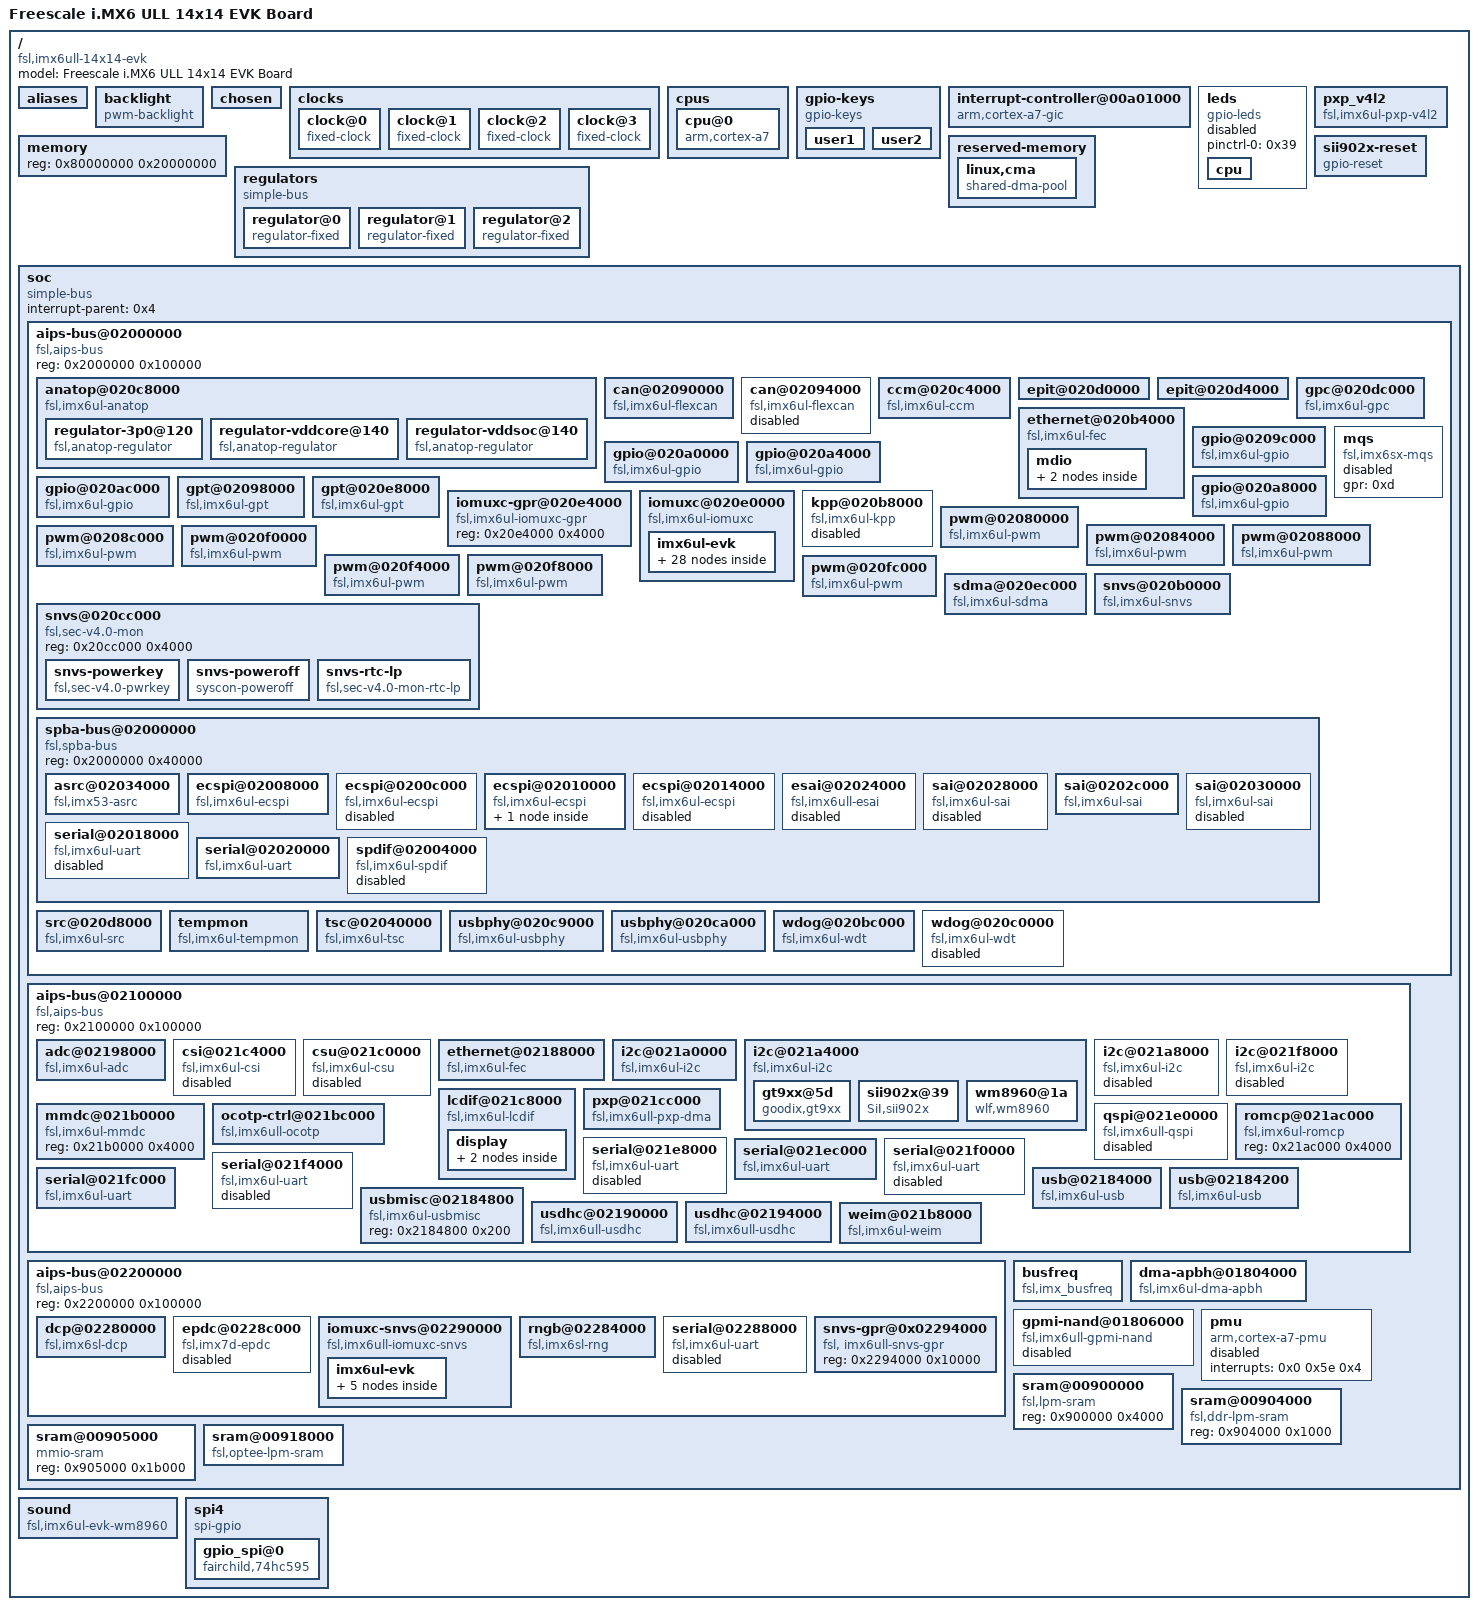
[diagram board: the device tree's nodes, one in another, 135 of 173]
/dts-v1/;

/memreserve/	0x0000000083000000 0x000000000000a000;
/ {
	#address-cells = <0x1>;
	#size-cells = <0x1>;
	compatible = "fsl,imx6ull-14x14-evk", "fsl,imx6ull";
	model = "Freescale i.MX6 ULL 14x14 EVK Board";

	aliases {
		can0 = "/soc/aips-bus@02000000/can@02090000";
		can1 = "/soc/aips-bus@02000000/can@02094000";
		ethernet0 = "/soc/aips-bus@02100000/ethernet@02188000";
		ethernet1 = "/soc/aips-bus@02000000/ethernet@020b4000";
		gpio0 = "/soc/aips-bus@02000000/gpio@0209c000";
		gpio1 = "/soc/aips-bus@02000000/gpio@020a0000";
		gpio2 = "/soc/aips-bus@02000000/gpio@020a4000";
		gpio3 = "/soc/aips-bus@02000000/gpio@020a8000";
		gpio4 = "/soc/aips-bus@02000000/gpio@020ac000";
		i2c0 = "/soc/aips-bus@02100000/i2c@021a0000";
		i2c1 = "/soc/aips-bus@02100000/i2c@021a4000";
		i2c2 = "/soc/aips-bus@02100000/i2c@021a8000";
		i2c3 = "/soc/aips-bus@02100000/i2c@021f8000";
		mmc0 = "/soc/aips-bus@02100000/usdhc@02190000";
		mmc1 = "/soc/aips-bus@02100000/usdhc@02194000";
		serial0 = "/soc/aips-bus@02000000/spba-bus@02000000/serial@02020000";
		serial1 = "/soc/aips-bus@02100000/serial@021e8000";
		serial2 = "/soc/aips-bus@02100000/serial@021ec000";
		serial3 = "/soc/aips-bus@02100000/serial@021f0000";
		serial4 = "/soc/aips-bus@02100000/serial@021f4000";
		serial5 = "/soc/aips-bus@02100000/serial@021fc000";
		serial6 = "/soc/aips-bus@02000000/spba-bus@02000000/serial@02018000";
		serial7 = "/soc/aips-bus@02200000/serial@02288000";
		spi0 = "/soc/aips-bus@02000000/spba-bus@02000000/ecspi@02008000";
		spi1 = "/soc/aips-bus@02000000/spba-bus@02000000/ecspi@0200c000";
		spi2 = "/soc/aips-bus@02000000/spba-bus@02000000/ecspi@02010000";
		spi3 = "/soc/aips-bus@02000000/spba-bus@02000000/ecspi@02014000";
		usbphy0 = "/soc/aips-bus@02000000/usbphy@020c9000";
		usbphy1 = "/soc/aips-bus@02000000/usbphy@020ca000";
	};

	backlight {
		brightness-levels = <0x0 0x1 0x2 0x3 0x4 0x5 0x6 0x8 0xa>;
		compatible = "pwm-backlight";
		default-brightness-level = <0x8>;
		pwms = <0x38 0x0 0x3e8>;
		status = "okay";
	};

	chosen {
		bootargs = "console=ttymxc0,115200 root=/dev/mmcblk1p2 rootwait rw";
		stdout-path = "/soc/aips-bus@02000000/spba-bus@02000000/serial@02020000";
	};

	clocks {
		#address-cells = <0x1>;
		#size-cells = <0x0>;

		clock@0 {
			#clock-cells = <0x0>;
			clock-frequency = <0x8000>;
			clock-output-names = "ckil";
			compatible = "fixed-clock";
			linux,phandle = <0x16>;
			phandle = <0x16>;
			reg = <0x0>;
		};

		clock@1 {
			#clock-cells = <0x0>;
			clock-frequency = <0x16e3600>;
			clock-output-names = "osc";
			compatible = "fixed-clock";
			linux,phandle = <0x17>;
			phandle = <0x17>;
			reg = <0x1>;
		};

		clock@2 {
			#clock-cells = <0x0>;
			clock-frequency = <0x0>;
			clock-output-names = "ipp_di0";
			compatible = "fixed-clock";
			linux,phandle = <0x18>;
			phandle = <0x18>;
			reg = <0x2>;
		};

		clock@3 {
			#clock-cells = <0x0>;
			clock-frequency = <0x0>;
			clock-output-names = "ipp_di1";
			compatible = "fixed-clock";
			linux,phandle = <0x19>;
			phandle = <0x19>;
			reg = <0x3>;
		};
	};

	cpus {
		#address-cells = <0x1>;
		#size-cells = <0x0>;

		cpu@0 {
			arm-supply = <0x2>;
			clock-latency = <0xee6c>;
			clock-names = "arm", "pll2_bus", "pll2_pfd2_396m", "secondary_sel", "step", "pll1_sw", "pll1_sys", "pll1_bypass", "pll1", "pll1_bypass_src", "osc";
			clocks = <0x1 0x5d 0x1 0x1a 0x1 0x26 0x1 0xdb 0x1 0x38 0x1 0x39 0x1 0x19 0x1 0x12 0x1 0xb 0x1 0x4 0x1 0x3>;
			compatible = "arm,cortex-a7";
			device_type = "cpu";
			fsl,low-power-run;
			fsl,soc-operating-points = <0xdbba0 0x11edd8 0xc15c0 0x11edd8 0x80e80 0x11edd8 0x60ae0 0x11edd8 0x30570 0x11edd8>;
			operating-points = <0xdbba0 0x137478 0xc15c0 0x12b128 0x80e80 0x11edd8 0x60ae0 0xfa3e8 0x30570 0xe7ef0>;
			reg = <0x0>;
			soc-supply = <0x3>;
		};
	};

	gpio-keys {
		compatible = "gpio-keys";
		pinctrl-names = "default";

		user1 {
			gpio-key,wakeup;
			gpios = <0x15 0x1 0x1>;
			label = "User1 Button";
			linux,code = <0x2>;
		};

		user2 {
			gpio-key,wakeup;
			gpios = <0x9 0xe 0x1>;
			label = "User2 Button";
			linux,code = <0x3>;
		};
	};

	interrupt-controller@00a01000 {
		#interrupt-cells = <0x3>;
		compatible = "arm,cortex-a7-gic";
		interrupt-controller;
		linux,phandle = <0x1e>;
		phandle = <0x1e>;
		reg = <0xa01000 0x1000 0xa02000 0x100>;
	};

	leds {
		compatible = "gpio-leds";
		pinctrl-0 = <0x39>;
		pinctrl-names = "default";
		status = "disabled";

		cpu {
			default-state = "on";
			gpios = <0x15 0x3 0x1>;
			label = "cpu";
			linux,default-trigger = "heartbeat";
		};
	};

	memory {
		device_type = "memory";
		reg = <0x80000000 0x20000000>;
	};

	pxp_v4l2 {
		compatible = "fsl,imx6ul-pxp-v4l2", "fsl,imx6sx-pxp-v4l2", "fsl,imx6sl-pxp-v4l2";
		status = "okay";
	};

	regulators {
		#address-cells = <0x1>;
		#size-cells = <0x0>;
		compatible = "simple-bus";

		regulator@0 {
			compatible = "regulator-fixed";
			linux,phandle = <0x12>;
			phandle = <0x12>;
			reg = <0x0>;
			regulator-max-microvolt = <0x325aa0>;
			regulator-min-microvolt = <0x325aa0>;
			regulator-name = "can-3v3";
		};

		regulator@1 {
			compatible = "regulator-fixed";
			enable-active-high;
			gpios = <0x15 0x5 0x0>;
			regulator-boot-on;
			regulator-max-microvolt = <0x39fbc0>;
			regulator-min-microvolt = <0x39fbc0>;
			regulator-name = "ltemodule-pwr";
		};

		regulator@2 {
			compatible = "regulator-fixed";
			gpios = <0xb 0xa 0x1>;
			regulator-boot-on;
			regulator-max-microvolt = <0x325aa0>;
			regulator-min-microvolt = <0x325aa0>;
			regulator-name = "wifi-pwr";
		};
	};

	reserved-memory {
		#address-cells = <0x1>;
		#size-cells = <0x1>;
		ranges;

		linux,cma {
			compatible = "shared-dma-pool";
			linux,cma-default;
			reusable;
			size = <0x14000000>;
		};
	};

	sii902x-reset {
		#reset-cells = <0x0>;
		compatible = "gpio-reset";
		linux,phandle = <0x2b>;
		phandle = <0x2b>;
		reset-delay-us = <0x186a0>;
		reset-gpios = <0x3e 0x1 0x1>;
		status = "okay";
	};

	soc {
		#address-cells = <0x1>;
		#size-cells = <0x1>;
		compatible = "simple-bus";
		interrupt-parent = <0x4>;
		ranges;

		aips-bus@02000000 {
			#address-cells = <0x1>;
			#size-cells = <0x1>;
			compatible = "fsl,aips-bus", "simple-bus";
			ranges;
			reg = <0x2000000 0x100000>;

			anatop@020c8000 {
				compatible = "fsl,imx6ul-anatop", "fsl,imx6q-anatop", "syscon", "simple-bus";
				interrupts = <0x0 0x31 0x4 0x0 0x36 0x4 0x0 0x7f 0x4>;
				linux,phandle = <0x1b>;
				phandle = <0x1b>;
				reg = <0x20c8000 0x1000>;

				regulator-3p0@120 {
					anatop-enable-bit = <0x0>;
					anatop-max-voltage = <0x33e140>;
					anatop-min-bit-val = <0x0>;
					anatop-min-voltage = <0x280de8>;
					anatop-reg-offset = <0x120>;
					anatop-vol-bit-shift = <0x8>;
					anatop-vol-bit-width = <0x5>;
					compatible = "fsl,anatop-regulator";
					linux,phandle = <0x1a>;
					phandle = <0x1a>;
					regulator-max-microvolt = <0x33e140>;
					regulator-min-microvolt = <0x280de8>;
					regulator-name = "vdd3p0";
				};

				regulator-vddcore@140 {
					anatop-delay-bit-shift = <0x18>;
					anatop-delay-bit-width = <0x2>;
					anatop-delay-reg-offset = <0x170>;
					anatop-max-voltage = <0x162010>;
					anatop-min-bit-val = <0x1>;
					anatop-min-voltage = <0xb1008>;
					anatop-reg-offset = <0x140>;
					anatop-vol-bit-shift = <0x0>;
					anatop-vol-bit-width = <0x5>;
					compatible = "fsl,anatop-regulator";
					linux,phandle = <0x2>;
					phandle = <0x2>;
					regulator-always-on;
					regulator-max-microvolt = <0x162010>;
					regulator-min-microvolt = <0xb1008>;
					regulator-name = "cpu";
				};

				regulator-vddsoc@140 {
					anatop-delay-bit-shift = <0x1c>;
					anatop-delay-bit-width = <0x2>;
					anatop-delay-reg-offset = <0x170>;
					anatop-max-voltage = <0x162010>;
					anatop-min-bit-val = <0x1>;
					anatop-min-voltage = <0xb1008>;
					anatop-reg-offset = <0x140>;
					anatop-vol-bit-shift = <0x12>;
					anatop-vol-bit-width = <0x5>;
					compatible = "fsl,anatop-regulator";
					linux,phandle = <0x3>;
					phandle = <0x3>;
					regulator-always-on;
					regulator-max-microvolt = <0x162010>;
					regulator-min-microvolt = <0xb1008>;
					regulator-name = "vddsoc";
				};
			};

			can@02090000 {
				clock-names = "ipg", "per";
				clocks = <0x1 0x94 0x1 0x95>;
				compatible = "fsl,imx6ul-flexcan", "fsl,imx6q-flexcan";
				interrupts = <0x0 0x6e 0x4>;
				pinctrl-0 = <0x11>;
				pinctrl-names = "default";
				reg = <0x2090000 0x4000>;
				status = "okay";
				stop-mode = <0xd 0x10 0x1 0x10 0x11>;
				xceiver-supply = <0x12>;
			};

			can@02094000 {
				clock-names = "ipg", "per";
				clocks = <0x1 0x96 0x1 0x97>;
				compatible = "fsl,imx6ul-flexcan", "fsl,imx6q-flexcan";
				interrupts = <0x0 0x6f 0x4>;
				reg = <0x2094000 0x4000>;
				status = "disabled";
				stop-mode = <0xd 0x10 0x2 0x10 0x12>;
			};

			ccm@020c4000 {
				#clock-cells = <0x1>;
				assigned-clock-rates = <0x2ee00000>;
				assigned-clocks = <0x1 0x32>;
				clock-names = "ckil", "osc", "ipp_di0", "ipp_di1";
				clocks = <0x16 0x17 0x18 0x19>;
				compatible = "fsl,imx6ul-ccm";
				interrupts = <0x0 0x57 0x4 0x0 0x58 0x4>;
				linux,phandle = <0x1>;
				phandle = <0x1>;
				reg = <0x20c4000 0x4000>;
			};

			epit@020d0000 {
				interrupts = <0x0 0x38 0x4>;
				reg = <0x20d0000 0x4000>;
			};

			epit@020d4000 {
				interrupts = <0x0 0x39 0x4>;
				reg = <0x20d4000 0x4000>;
			};

			ethernet@020b4000 {
				clock-names = "ipg", "ahb", "ptp", "enet_clk_ref", "enet_out";
				clocks = <0x1 0x90 0x1 0x91 0x1 0x30 0x1 0x2e 0x1 0x2e>;
				compatible = "fsl,imx6ul-fec", "fsl,imx6q-fec";
				fsl,magic-packet;
				fsl,num-rx-queues = <0x1>;
				fsl,num-tx-queues = <0x1>;
				fsl,wakeup_irq = <0x0>;
				interrupts = <0x0 0x78 0x4 0x0 0x79 0x4>;
				local-mac-address = [00 01 3f 2d 3e 4d];
				phy-handle = <0x14>;
				phy-mode = "rmii";
				phy-reset-duration = <0x1a>;
				phy-reset-gpios = <0x15 0x6 0x1>;
				pinctrl-0 = <0x13>;
				pinctrl-names = "default";
				reg = <0x20b4000 0x4000>;
				status = "okay";
				stop-mode = <0xd 0x10 0x4>;

				mdio {
					#address-cells = <0x1>;
					#size-cells = <0x0>;

					ethernet-phy@0 {
						compatible = "ethernet-phy-ieee802.3-c22";
						linux,phandle = <0x24>;
						phandle = <0x24>;
						reg = <0x0>;
						smsc,disable-energy-detect;
					};

					ethernet-phy@1 {
						compatible = "ethernet-phy-ieee802.3-c22";
						linux,phandle = <0x14>;
						phandle = <0x14>;
						reg = <0x1>;
						smsc,disable-energy-detect;
					};
				};
			};

			gpc@020dc000 {
				#interrupt-cells = <0x3>;
				compatible = "fsl,imx6ul-gpc", "fsl,imx6q-gpc";
				fsl,cpu_pdnscr_iso = <0x1>;
				fsl,cpu_pdnscr_iso2sw = <0x1>;
				fsl,cpu_pupscr_sw = <0x0>;
				fsl,cpu_pupscr_sw2iso = <0x1>;
				fsl,ldo-bypass = <0x0>;
				fsl,mf-mix-wakeup-irq = <0xfc00000 0x7d00 0x0 0x1400640>;
				interrupt-controller;
				interrupt-parent = <0x1e>;
				interrupts = <0x0 0x59 0x4>;
				linux,phandle = <0x4>;
				phandle = <0x4>;
				reg = <0x20dc000 0x4000>;
			};

			gpio@0209c000 {
				#gpio-cells = <0x2>;
				#interrupt-cells = <0x2>;
				compatible = "fsl,imx6ul-gpio", "fsl,imx35-gpio";
				gpio-controller;
				interrupt-controller;
				interrupts = <0x0 0x42 0x4 0x0 0x43 0x4>;
				linux,phandle = <0xb>;
				phandle = <0xb>;
				reg = <0x209c000 0x4000>;
			};

			gpio@020a0000 {
				#gpio-cells = <0x2>;
				#interrupt-cells = <0x2>;
				compatible = "fsl,imx6ul-gpio", "fsl,imx35-gpio";
				gpio-controller;
				interrupt-controller;
				interrupts = <0x0 0x44 0x4 0x0 0x45 0x4>;
				reg = <0x20a0000 0x4000>;
			};

			gpio@020a4000 {
				#gpio-cells = <0x2>;
				#interrupt-cells = <0x2>;
				compatible = "fsl,imx6ul-gpio", "fsl,imx35-gpio";
				gpio-controller;
				interrupt-controller;
				interrupts = <0x0 0x46 0x4 0x0 0x47 0x4>;
				linux,phandle = <0x32>;
				phandle = <0x32>;
				reg = <0x20a4000 0x4000>;
			};

			gpio@020a8000 {
				#gpio-cells = <0x2>;
				#interrupt-cells = <0x2>;
				compatible = "fsl,imx6ul-gpio", "fsl,imx35-gpio";
				gpio-controller;
				interrupt-controller;
				interrupts = <0x0 0x48 0x4 0x0 0x49 0x4>;
				linux,phandle = <0x9>;
				phandle = <0x9>;
				reg = <0x20a8000 0x4000>;
			};

			gpio@020ac000 {
				#gpio-cells = <0x2>;
				#interrupt-cells = <0x2>;
				compatible = "fsl,imx6ul-gpio", "fsl,imx35-gpio";
				gpio-controller;
				interrupt-controller;
				interrupts = <0x0 0x4a 0x4 0x0 0x4b 0x4>;
				linux,phandle = <0x15>;
				phandle = <0x15>;
				reg = <0x20ac000 0x4000>;
			};

			gpt@02098000 {
				clock-names = "ipg", "osc_per";
				clocks = <0x1 0x98 0x1 0xd6>;
				compatible = "fsl,imx6ul-gpt", "fsl,imx31-gpt";
				interrupts = <0x0 0x37 0x4>;
				reg = <0x2098000 0x4000>;
			};

			gpt@020e8000 {
				clock-names = "ipg", "per";
				clocks = <0x1 0x0 0x1 0x0>;
				compatible = "fsl,imx6ul-gpt", "fsl,imx31-gpt";
				interrupts = <0x0 0x6d 0x4>;
				reg = <0x20e8000 0x4000>;
			};

			iomuxc-gpr@020e4000 {
				compatible = "fsl,imx6ul-iomuxc-gpr", "fsl,imx6q-iomuxc-gpr", "syscon";
				linux,phandle = <0xd>;
				phandle = <0xd>;
				reg = <0x20e4000 0x4000>;
			};

			iomuxc@020e0000 {
				compatible = "fsl,imx6ul-iomuxc";
				pinctrl-0 = <0x1f>;
				pinctrl-names = "default";
				reg = <0x20e0000 0x4000>;

				imx6ul-evk {

					adc1grp {
						fsl,pins = <0x68 0x2f4 0x0 0x5 0x0 0x10b1 0x6c 0x2f8 0x0 0x5 0x0 0x10b1>;
						linux,phandle = <0x27>;
						phandle = <0x27>;
					};

					ecspi1 {
						fsl,pins = <0x1f4 0x480 0x534 0x3 0x1 0x10b0 0x1fc 0x488 0x53c 0x3 0x1 0x10b0 0x200 0x48c 0x538 0x3 0x1 0x10b0 0x1f8 0x484 0x0 0x5 0x0 0x10b0 0x1f0 0x47c 0x0 0x5 0x0 0x10b0>;
						linux,phandle = <0x8>;
						phandle = <0x8>;
					};

					ecspi3 {
						fsl,pins = <0x9c 0x328 0x55c 0x8 0x0 0x10b0 0xa0 0x32c 0x558 0x8 0x0 0x10b0 0x98 0x324 0x554 0x8 0x0 0x10b0 0x94 0x320 0x0 0x5 0x0 0x10b0 0x60 0x2ec 0x0 0x5 0x0 0x10b0>;
						linux,phandle = <0xa>;
						phandle = <0xa>;
					};

					enet1grp {
						fsl,pins;
						linux,phandle = <0x23>;
						phandle = <0x23>;
					};

					enet2grp {
						fsl,pins = <0x74 0x300 0x580 0x1 0x0 0x1b0b0 0x78 0x304 0x0 0x1 0x0 0x1b0b0 0xec 0x378 0x0 0x0 0x0 0x1b0b0 0x100 0x38c 0x0 0x0 0x0 0x1b0b0 0xe4 0x370 0x0 0x0 0x0 0x1b0b0 0xe8 0x374 0x0 0x0 0x0 0x1b0b0 0xf8 0x384 0x0 0x0 0x0 0x1b0b0 0xf0 0x37c 0x0 0x0 0x0 0x1b0b0 0xf4 0x380 0x0 0x0 0x0 0x1b0b0 0xfc 0x388 0x57c 0x4 0x2 0x4001b031 0xcc 0x358 0x0 0x0 0x0 0x1b0b0 0xe0 0x36c 0x0 0x0 0x0 0x1b0b0 0xc4 0x350 0x0 0x0 0x0 0x1b0b0 0xc8 0x354 0x0 0x0 0x0 0x1b0b0 0xd8 0x364 0x0 0x0 0x0 0x1b0b0 0xd0 0x35c 0x0 0x0 0x0 0x1b0b0 0xd4 0x360 0x0 0x0 0x0 0x1b0b0 0xdc 0x368 0x574 0x4 0x2 0x4001b031>;
						linux,phandle = <0x13>;
						phandle = <0x13>;
					};

					flexcan1grp {
						fsl,pins = <0xac 0x338 0x0 0x2 0x0 0x10b0 0xb0 0x33c 0x584 0x2 0x0 0x10b0>;
						linux,phandle = <0x11>;
						phandle = <0x11>;
					};

					hdmigrp {
						fsl,pins = <0x8c 0x318 0x0 0x5 0x0 0x59>;
						linux,phandle = <0x2a>;
						phandle = <0x2a>;
					};

					hoggrp-1 {
						fsl,pins = <0x90 0x31c 0x0 0x5 0x0 0x17059 0x5c 0x2e8 0x4b8 0x2 0x0 0x17059 0x1c 0x60 0x0 0x5 0x0 0x110a0>;
						linux,phandle = <0x1f>;
						phandle = <0x1f>;
					};

					i2c1grp {
						fsl,pins = <0xb4 0x340 0x5a4 0x2 0x1 0x4001b8b0 0xb8 0x344 0x5a8 0x2 0x2 0x4001b8b0>;
						linux,phandle = <0x28>;
						phandle = <0x28>;
					};

					i2c2grp {
						fsl,pins = <0xbc 0x348 0x5ac 0x2 0x2 0x4001b8b0 0xc0 0x34c 0x5b0 0x2 0x2 0x4001b8b0>;
						linux,phandle = <0x29>;
						phandle = <0x29>;
					};

					lcdif_tsc_int {
						fsl,pins = <0x70 0x2fc 0x0 0x5 0x0 0x10b0>;
						linux,phandle = <0x2d>;
						phandle = <0x2d>;
					};

					lcdifctrlgrp {
						fsl,pins = <0x104 0x390 0x0 0x0 0x0 0x79 0x108 0x394 0x0 0x0 0x0 0x79 0x10c 0x398 0x5dc 0x0 0x0 0x79 0x110 0x39c 0x0 0x0 0x0 0x79>;
						linux,phandle = <0x2f>;
						phandle = <0x2f>;
					};

					lcdifdatgrp {
						fsl,pins = <0x118 0x3a4 0x0 0x0 0x0 0x79 0x11c 0x3a8 0x0 0x0 0x0 0x79 0x120 0x3ac 0x0 0x0 0x0 0x79 0x124 0x3b0 0x0 0x0 0x0 0x79 0x128 0x3b4 0x0 0x0 0x0 0x79 0x12c 0x3b8 0x0 0x0 0x0 0x79 0x130 0x3bc 0x0 0x0 0x0 0x79 0x134 0x3c0 0x0 0x0 0x0 0x79 0x138 0x3c4 0x0 0x0 0x0 0x79 0x13c 0x3c8 0x0 0x0 0x0 0x79 0x140 0x3cc 0x0 0x0 0x0 0x79 0x144 0x3d0 0x0 0x0 0x0 0x79 0x148 0x3d4 0x0 0x0 0x0 0x79 0x14c 0x3d8 0x0 0x0 0x0 0x79 0x150 0x3dc 0x0 0x0 0x0 0x79 0x154 0x3e0 0x0 0x0 0x0 0x79 0x158 0x3e4 0x0 0x0 0x0 0x79 0x15c 0x3e8 0x0 0x0 0x0 0x79 0x160 0x3ec 0x0 0x0 0x0 0x79 0x164 0x3f0 0x0 0x0 0x0 0x79 0x168 0x3f4 0x0 0x0 0x0 0x79 0x16c 0x3f8 0x0 0x0 0x0 0x79 0x170 0x3fc 0x0 0x0 0x0 0x79 0x174 0x400 0x0 0x0 0x0 0x79>;
						linux,phandle = <0x2e>;
						phandle = <0x2e>;
					};

					lcdifdatgrp_16bits {
						fsl,pins = <0x118 0x3a4 0x0 0x0 0x0 0x79 0x11c 0x3a8 0x0 0x0 0x0 0x79 0x120 0x3ac 0x0 0x0 0x0 0x79 0x124 0x3b0 0x0 0x0 0x0 0x79 0x128 0x3b4 0x0 0x0 0x0 0x79 0x12c 0x3b8 0x0 0x0 0x0 0x79 0x130 0x3bc 0x0 0x0 0x0 0x79 0x134 0x3c0 0x0 0x0 0x0 0x79 0x138 0x3c4 0x0 0x0 0x0 0x79 0x13c 0x3c8 0x0 0x0 0x0 0x79 0x140 0x3cc 0x0 0x0 0x0 0x79 0x144 0x3d0 0x0 0x0 0x0 0x79 0x148 0x3d4 0x0 0x0 0x0 0x79 0x14c 0x3d8 0x0 0x0 0x0 0x79 0x150 0x3dc 0x0 0x0 0x0 0x79 0x154 0x3e0 0x0 0x0 0x0 0x79>;
					};

					lcdifresetgrp {
						fsl,pins = <0x114 0x3a0 0x0 0x5 0x0 0x1b0b0>;
						linux,phandle = <0x30>;
						phandle = <0x30>;
					};

					pwm1grp {
						fsl,pins = <0x7c 0x308 0x0 0x0 0x0 0x110b0>;
						linux,phandle = <0x10>;
						phandle = <0x10>;
					};

					sai2grp {
						fsl,pins = <0x50 0x2dc 0x5f8 0x2 0x0 0x17088 0x4c 0x2d8 0x5fc 0x2 0x0 0x17088 0x58 0x2e4 0x0 0x2 0x0 0x11088 0x54 0x2e0 0x5f4 0x2 0x0 0x11088 0x48 0x2d4 0x5f0 0x2 0x0 0x17088>;
						linux,phandle = <0xe>;
						phandle = <0xe>;
					};

					tscgrp {
						fsl,pins = <0x60 0x2ec 0x0 0x5 0x0 0xb0 0x64 0x2f0 0x0 0x5 0x0 0xb0 0x68 0x2f4 0x0 0x5 0x0 0xb0 0x6c 0x2f8 0x0 0x5 0x0 0xb0>;
						linux,phandle = <0xf>;
						phandle = <0xf>;
					};

					uart1grp {
						fsl,pins = <0x84 0x310 0x0 0x0 0x0 0x1b0b1 0x88 0x314 0x624 0x0 0x3 0x1b0b1>;
						linux,phandle = <0xc>;
						phandle = <0xc>;
					};

					uart3grp {
						fsl,pins = <0xa4 0x330 0x0 0x0 0x0 0x1b0b1 0xa8 0x334 0x634 0x0 0x1 0x1b0b1>;
						linux,phandle = <0x34>;
						phandle = <0x34>;
					};

					uart6grp {
						fsl,pins = <0x1d4 0x460 0x0 0x8 0x0 0x1b0b1 0x1d8 0x464 0x64c 0x8 0x3 0x1b0b1>;
						linux,phandle = <0x36>;
						phandle = <0x36>;
					};

					usdhc1grp {
						fsl,pins = <0x1bc 0x448 0x0 0x0 0x0 0x17059 0x1c0 0x44c 0x0 0x0 0x0 0x10071 0x1c4 0x450 0x0 0x0 0x0 0x17059 0x1c8 0x454 0x0 0x0 0x0 0x17059 0x1cc 0x458 0x0 0x0 0x0 0x17059 0x1d0 0x45c 0x0 0x0 0x0 0x17059>;
						linux,phandle = <0x25>;
						phandle = <0x25>;
					};

					usdhc1grp100mhz {
						fsl,pins = <0x1bc 0x448 0x0 0x0 0x0 0x170b9 0x1c0 0x44c 0x0 0x0 0x0 0x100b9 0x1c4 0x450 0x0 0x0 0x0 0x170b9 0x1c8 0x454 0x0 0x0 0x0 0x170b9 0x1cc 0x458 0x0 0x0 0x0 0x170b9 0x1d0 0x45c 0x0 0x0 0x0 0x170b9>;
					};

					usdhc1grp200mhz {
						fsl,pins = <0x1bc 0x448 0x0 0x0 0x0 0x170f9 0x1c0 0x44c 0x0 0x0 0x0 0x100f9 0x1c4 0x450 0x0 0x0 0x0 0x170f9 0x1c8 0x454 0x0 0x0 0x0 0x170f9 0x1cc 0x458 0x0 0x0 0x0 0x170f9 0x1d0 0x45c 0x0 0x0 0x0 0x170f9>;
					};

					usdhc2grp {
						fsl,pins = <0x178 0x404 0x670 0x1 0x2 0x10069 0x17c 0x408 0x678 0x1 0x2 0x17059 0x180 0x40c 0x67c 0x1 0x2 0x17059 0x184 0x410 0x680 0x1 0x2 0x17059 0x188 0x414 0x684 0x1 0x1 0x17059 0x18c 0x418 0x688 0x1 0x2 0x17059>;
					};

					usdhc2grp_8bit {
						fsl,pins = <0x178 0x404 0x670 0x1 0x2 0x10069 0x17c 0x408 0x678 0x1 0x2 0x17059 0x180 0x40c 0x67c 0x1 0x2 0x17059 0x184 0x410 0x680 0x1 0x2 0x17059 0x188 0x414 0x684 0x1 0x1 0x17059 0x18c 0x418 0x688 0x1 0x2 0x17059 0x190 0x41c 0x68c 0x1 0x1 0x17059 0x194 0x420 0x690 0x1 0x1 0x17059 0x198 0x424 0x694 0x1 0x1 0x17059 0x19c 0x428 0x698 0x1 0x1 0x17059>;
						linux,phandle = <0x26>;
						phandle = <0x26>;
					};

					usdhc2grp_8bit_100mhz {
						fsl,pins = <0x178 0x404 0x670 0x1 0x2 0x100b9 0x17c 0x408 0x678 0x1 0x2 0x170b9 0x180 0x40c 0x67c 0x1 0x2 0x170b9 0x184 0x410 0x680 0x1 0x2 0x170b9 0x188 0x414 0x684 0x1 0x1 0x170b9 0x18c 0x418 0x688 0x1 0x2 0x170b9 0x190 0x41c 0x68c 0x1 0x1 0x170b9 0x194 0x420 0x690 0x1 0x1 0x170b9 0x198 0x424 0x694 0x1 0x1 0x170b9 0x19c 0x428 0x698 0x1 0x1 0x170b9>;
					};

					usdhc2grp_8bit_200mhz {
						fsl,pins = <0x178 0x404 0x670 0x1 0x2 0x100f9 0x17c 0x408 0x678 0x1 0x2 0x170f9 0x180 0x40c 0x67c 0x1 0x2 0x170f9 0x184 0x410 0x680 0x1 0x2 0x170f9 0x188 0x414 0x684 0x1 0x1 0x170f9 0x18c 0x418 0x688 0x1 0x2 0x170f9 0x190 0x41c 0x68c 0x1 0x1 0x170f9 0x194 0x420 0x690 0x1 0x1 0x170f9 0x198 0x424 0x694 0x1 0x1 0x170f9 0x19c 0x428 0x698 0x1 0x1 0x170f9>;
					};
				};
			};

			kpp@020b8000 {
				clocks = <0x1 0x0>;
				compatible = "fsl,imx6ul-kpp", "fsl,imx21-kpp";
				interrupts = <0x0 0x52 0x4>;
				reg = <0x20b8000 0x4000>;
				status = "disabled";
			};

			mqs {
				compatible = "fsl,imx6sx-mqs";
				gpr = <0xd>;
				status = "disabled";
			};

			pwm@02080000 {
				#pwm-cells = <0x2>;
				clock-names = "ipg", "per";
				clocks = <0x1 0xa7 0x1 0xa7>;
				compatible = "fsl,imx6ul-pwm", "fsl,imx27-pwm";
				interrupts = <0x0 0x53 0x4>;
				linux,phandle = <0x38>;
				phandle = <0x38>;
				pinctrl-0 = <0x10>;
				pinctrl-names = "default";
				reg = <0x2080000 0x4000>;
				status = "okay";
			};

			pwm@02084000 {
				#pwm-cells = <0x2>;
				clock-names = "ipg", "per";
				clocks = <0x1 0x0 0x1 0x0>;
				compatible = "fsl,imx6ul-pwm", "fsl,imx27-pwm";
				interrupts = <0x0 0x54 0x4>;
				reg = <0x2084000 0x4000>;
			};

			pwm@02088000 {
				#pwm-cells = <0x2>;
				clock-names = "ipg", "per";
				clocks = <0x1 0xa9 0x1 0xa9>;
				compatible = "fsl,imx6ul-pwm", "fsl,imx27-pwm";
				interrupts = <0x0 0x55 0x4>;
				reg = <0x2088000 0x4000>;
			};

			pwm@0208c000 {
				#pwm-cells = <0x2>;
				clock-names = "ipg", "per";
				clocks = <0x1 0x0 0x1 0x0>;
				compatible = "fsl,imx6ul-pwm", "fsl,imx27-pwm";
				interrupts = <0x0 0x56 0x4>;
				reg = <0x208c000 0x4000>;
			};

			pwm@020f0000 {
				#pwm-cells = <0x2>;
				clock-names = "ipg", "per";
				clocks = <0x1 0x0 0x1 0x0>;
				compatible = "fsl,imx6ul-pwm", "fsl,imx27-pwm";
				interrupts = <0x0 0x72 0x4>;
				reg = <0x20f0000 0x4000>;
			};

			pwm@020f4000 {
				#pwm-cells = <0x2>;
				clock-names = "ipg", "per";
				clocks = <0x1 0x0 0x1 0x0>;
				compatible = "fsl,imx6ul-pwm", "fsl,imx27-pwm";
				interrupts = <0x0 0x73 0x4>;
				reg = <0x20f4000 0x4000>;
			};

			pwm@020f8000 {
				#pwm-cells = <0x2>;
				clock-names = "ipg", "per";
				clocks = <0x1 0x0 0x1 0x0>;
				compatible = "fsl,imx6ul-pwm", "fsl,imx27-pwm";
				interrupts = <0x0 0x74 0x4>;
				reg = <0x20f8000 0x4000>;
			};

			pwm@020fc000 {
				#pwm-cells = <0x2>;
				clock-names = "ipg", "per";
				clocks = <0x1 0x0 0x1 0x0>;
				compatible = "fsl,imx6ul-pwm", "fsl,imx27-pwm";
				interrupts = <0x0 0x75 0x4>;
				reg = <0x20fc000 0x4000>;
			};

			sdma@020ec000 {
				#dma-cells = <0x3>;
				clock-names = "ipg", "ahb";
				clocks = <0x1 0xb8 0x1 0xb8>;
				compatible = "fsl,imx6ul-sdma", "fsl,imx35-sdma";
				fsl,sdma-ram-script-name = "imx/sdma/sdma-imx6q.bin";
				interrupts = <0x0 0x2 0x4>;
				iram = <0x5>;
				linux,phandle = <0x7>;
				phandle = <0x7>;
				reg = <0x20ec000 0x4000>;
			};

			snvs@020b0000 {
				compatible = "fsl,imx6ul-snvs";
				interrupts = <0x0 0x4 0x4>;
				reg = <0x20b0000 0x4000>;
			};

			snvs@020cc000 {
				compatible = "fsl,sec-v4.0-mon", "syscon", "simple-mfd";
				linux,phandle = <0x1d>;
				phandle = <0x1d>;
				reg = <0x20cc000 0x4000>;

				snvs-powerkey {
					compatible = "fsl,sec-v4.0-pwrkey";
					interrupts = <0x0 0x4 0x4>;
					linux,keycode = <0x74>;
					regmap = <0x1d>;
					wakeup-source;
				};

				snvs-poweroff {
					compatible = "syscon-poweroff";
					mask = <0x61>;
					offset = <0x38>;
					regmap = <0x1d>;
				};

				snvs-rtc-lp {
					compatible = "fsl,sec-v4.0-mon-rtc-lp";
					interrupts = <0x0 0x13 0x4 0x0 0x14 0x4>;
					offset = <0x34>;
					regmap = <0x1d>;
				};
			};

			spba-bus@02000000 {
				#address-cells = <0x1>;
				#size-cells = <0x1>;
				compatible = "fsl,spba-bus", "simple-bus";
				ranges;
				reg = <0x2000000 0x40000>;

				asrc@02034000 {
					clock-names = "mem", "ipg", "asrck_0", "asrck_1", "asrck_2", "asrck_3", "asrck_4", "asrck_5", "asrck_6", "asrck_7", "asrck_8", "asrck_9", "asrck_a", "asrck_b", "asrck_c", "asrck_d", "asrck_e", "asrck_f", "spba";
					clocks = <0x1 0x81 0x1 0x82 0x1 0x0 0x1 0x0 0x1 0x0 0x1 0x0 0x1 0x0 0x1 0x0 0x1 0x0 0x1 0x0 0x1 0x0 0x1 0x0 0x1 0x0 0x1 0x0 0x1 0x0 0x1 0xbc 0x1 0x0 0x1 0x0 0x1 0xbb>;
					compatible = "fsl,imx53-asrc";
					dma-names = "rxa", "rxb", "rxc", "txa", "txb", "txc";
					dmas = <0x7 0x11 0x17 0x1 0x7 0x12 0x17 0x1 0x7 0x13 0x17 0x1 0x7 0x14 0x17 0x1 0x7 0x15 0x17 0x1 0x7 0x16 0x17 0x1>;
					fsl,asrc-rate = <0xbb80>;
					fsl,asrc-width = <0x10>;
					interrupts = <0x0 0x32 0x4>;
					linux,phandle = <0x3c>;
					phandle = <0x3c>;
					reg = <0x2034000 0x4000>;
					status = "okay";
				};

				ecspi@02008000 {
					#address-cells = <0x1>;
					#size-cells = <0x0>;
					clock-names = "ipg", "per";
					clocks = <0x1 0x8b 0x1 0x8b>;
					compatible = "fsl,imx6ul-ecspi", "fsl,imx51-ecspi";
					cs-gpios = <0x9 0x1a 0x1 0x9 0x18 0x1>;
					dma-names = "rx", "tx";
					dmas = <0x7 0x3 0x7 0x1 0x7 0x4 0x7 0x2>;
					fsl,spi-num-chipselects = <0x2>;
					interrupts = <0x0 0x1f 0x4>;
					pinctrl-0 = <0x8>;
					pinctrl-names = "default";
					reg = <0x2008000 0x4000>;
					status = "okay";
				};

				ecspi@0200c000 {
					#address-cells = <0x1>;
					#size-cells = <0x0>;
					clock-names = "ipg", "per";
					clocks = <0x1 0x8c 0x1 0x8c>;
					compatible = "fsl,imx6ul-ecspi", "fsl,imx51-ecspi";
					dma-names = "rx", "tx";
					dmas = <0x7 0x5 0x7 0x1 0x7 0x6 0x7 0x2>;
					interrupts = <0x0 0x20 0x4>;
					reg = <0x200c000 0x4000>;
					status = "disabled";
				};

				ecspi@02010000 {
					#address-cells = <0x1>;
					#size-cells = <0x0>;
					clock-names = "ipg", "per";
					clocks = <0x1 0x8d 0x1 0x8d>;
					compatible = "fsl,imx6ul-ecspi", "fsl,imx51-ecspi";
					cs-gpios = <0xb 0x14 0x1>;
					dma-names = "rx", "tx";
					dmas = <0x7 0x7 0x7 0x1 0x7 0x8 0x7 0x2>;
					interrupts = <0x0 0x21 0x4>;
					pinctrl-0 = <0xa>;
					pinctrl-names = "default";
					reg = <0x2010000 0x4000>;
					status = "okay";

					icm20608@0 {
						compatible = "invensense,icm20608";
						interrupt-parent = <0xb>;
						interrupts = <0x1 0x1>;
						reg = <0x0>;
						spi-max-frequency = <0x7a1200>;
					};
				};

				ecspi@02014000 {
					#address-cells = <0x1>;
					#size-cells = <0x0>;
					clock-names = "ipg", "per";
					clocks = <0x1 0x8e 0x1 0x8e>;
					compatible = "fsl,imx6ul-ecspi", "fsl,imx51-ecspi";
					dma-names = "rx", "tx";
					dmas = <0x7 0x9 0x7 0x1 0x7 0xa 0x7 0x2>;
					interrupts = <0x0 0x22 0x4>;
					reg = <0x2014000 0x4000>;
					status = "disabled";
				};

				esai@02024000 {
					clock-names = "core", "mem", "extal", "fsys", "spba";
					clocks = <0x1 0xe6 0x1 0xe5 0x1 0xe4 0x1 0xe6 0x1 0xbb>;
					compatible = "fsl,imx6ull-esai";
					dma-names = "rx", "tx";
					dma-source = <0xd 0x0 0xe 0x0 0xf>;
					dmas = <0x7 0x0 0x15 0x0 0x7 0x2f 0x15 0x0>;
					interrupts = <0x0 0x33 0x4>;
					reg = <0x2024000 0x4000>;
					status = "disabled";
				};

				sai@02028000 {
					clock-names = "bus", "mclk0", "mclk1", "mclk2", "mclk3";
					clocks = <0x1 0xb3 0x1 0x0 0x1 0xb2 0x1 0x0 0x1 0x0>;
					compatible = "fsl,imx6ul-sai", "fsl,imx6sx-sai";
					dma-names = "rx", "tx";
					dmas = <0x7 0x23 0x18 0x0 0x7 0x24 0x18 0x0>;
					interrupts = <0x0 0x61 0x4>;
					reg = <0x2028000 0x4000>;
					status = "disabled";
				};

				sai@0202c000 {
					assigned-clock-parents = <0x1 0x32>;
					assigned-clock-rates = <0x0 0xbb8000>;
					assigned-clocks = <0x1 0x47 0x1 0xb4>;
					clock-names = "bus", "mclk0", "mclk1", "mclk2", "mclk3";
					clocks = <0x1 0xb5 0x1 0x0 0x1 0xb4 0x1 0x0 0x1 0x0>;
					compatible = "fsl,imx6ul-sai", "fsl,imx6sx-sai";
					dma-names = "rx", "tx";
					dmas = <0x7 0x25 0x18 0x0 0x7 0x26 0x18 0x0>;
					interrupts = <0x0 0x62 0x4>;
					linux,phandle = <0x3a>;
					phandle = <0x3a>;
					pinctrl-0 = <0xe>;
					pinctrl-names = "default";
					reg = <0x202c000 0x4000>;
					status = "okay";
				};

				sai@02030000 {
					clock-names = "bus", "mclk0", "mclk1", "mclk2", "mclk3";
					clocks = <0x1 0xb7 0x1 0x0 0x1 0xb6 0x1 0x0 0x1 0x0>;
					compatible = "fsl,imx6ul-sai", "fsl,imx6sx-sai";
					dma-names = "rx", "tx";
					dmas = <0x7 0x27 0x18 0x0 0x7 0x28 0x18 0x0>;
					interrupts = <0x0 0x18 0x4>;
					reg = <0x2030000 0x4000>;
					status = "disabled";
				};

				serial@02018000 {
					clock-names = "ipg", "per";
					clocks = <0x1 0xc9 0x1 0xca>;
					compatible = "fsl,imx6ul-uart", "fsl,imx6q-uart", "fsl,imx21-uart";
					dma-names = "rx", "tx";
					dmas = <0x7 0x2b 0x4 0x0 0x7 0x2c 0x4 0x0>;
					interrupts = <0x0 0x27 0x4>;
					reg = <0x2018000 0x4000>;
					status = "disabled";
				};

				serial@02020000 {
					clock-names = "ipg", "per";
					clocks = <0x1 0xbd 0x1 0xbe>;
					compatible = "fsl,imx6ul-uart", "fsl,imx6q-uart", "fsl,imx21-uart";
					interrupts = <0x0 0x1a 0x4>;
					pinctrl-0 = <0xc>;
					pinctrl-names = "default";
					reg = <0x2020000 0x4000>;
					status = "okay";
				};

				spdif@02004000 {
					clock-names = "core", "rxtx0", "rxtx1", "rxtx2", "rxtx3", "rxtx4", "rxtx5", "rxtx6", "rxtx7", "spba";
					clocks = <0x1 0xd5 0x1 0x3 0x1 0xbc 0x1 0x0 0x1 0x0 0x1 0x0 0x1 0x64 0x1 0x0 0x1 0x0 0x1 0xbb>;
					compatible = "fsl,imx6ul-spdif", "fsl,imx35-spdif";
					dma-names = "rx", "tx";
					dmas = <0x7 0x29 0x12 0x0 0x7 0x2a 0x12 0x0>;
					interrupts = <0x0 0x34 0x4>;
					reg = <0x2004000 0x4000>;
					status = "disabled";
				};
			};

			src@020d8000 {
				#reset-cells = <0x1>;
				compatible = "fsl,imx6ul-src", "fsl,imx51-src";
				interrupts = <0x0 0x5b 0x4 0x0 0x60 0x4>;
				reg = <0x20d8000 0x4000>;
			};

			tempmon {
				clocks = <0x1 0x1b>;
				compatible = "fsl,imx6ul-tempmon", "fsl,imx6sx-tempmon";
				fsl,tempmon = <0x1b>;
				fsl,tempmon-data = <0x1c>;
				interrupts = <0x0 0x31 0x4>;
			};

			tsc@02040000 {
				clock-names = "tsc", "adc";
				clocks = <0x1 0x64 0x1 0x7c>;
				compatible = "fsl,imx6ul-tsc";
				interrupts = <0x0 0x3 0x4 0x0 0x65 0x4>;
				measure-delay-time = <0xfffff>;
				pinctrl-0 = <0xf>;
				pinctrl-names = "default";
				pre-charge-time = <0xffff>;
				reg = <0x2040000 0x4000 0x219c000 0x4000>;
				status = "okay";
				xnur-gpio = <0xb 0x3 0x1>;
			};

			usbphy@020c9000 {
				clocks = <0x1 0x20>;
				compatible = "fsl,imx6ul-usbphy", "fsl,imx23-usbphy";
				fsl,anatop = <0x1b>;
				interrupts = <0x0 0x2c 0x4>;
				linux,phandle = <0x20>;
				phandle = <0x20>;
				phy-3p0-supply = <0x1a>;
				reg = <0x20c9000 0x1000>;
				tx-d-cal = <0x5>;
			};

			usbphy@020ca000 {
				clocks = <0x1 0x21>;
				compatible = "fsl,imx6ul-usbphy", "fsl,imx23-usbphy";
				fsl,anatop = <0x1b>;
				interrupts = <0x0 0x2d 0x4>;
				linux,phandle = <0x22>;
				phandle = <0x22>;
				phy-3p0-supply = <0x1a>;
				reg = <0x20ca000 0x1000>;
				tx-d-cal = <0x5>;
			};

			wdog@020bc000 {
				clocks = <0x1 0xd0>;
				compatible = "fsl,imx6ul-wdt", "fsl,imx21-wdt";
				interrupts = <0x0 0x50 0x4>;
				reg = <0x20bc000 0x4000>;
				status = "okay";
			};

			wdog@020c0000 {
				clocks = <0x1 0xd1>;
				compatible = "fsl,imx6ul-wdt", "fsl,imx21-wdt";
				interrupts = <0x0 0x51 0x4>;
				reg = <0x20c0000 0x4000>;
				status = "disabled";
			};
		};

		aips-bus@02100000 {
			#address-cells = <0x1>;
			#size-cells = <0x1>;
			compatible = "fsl,aips-bus", "simple-bus";
			ranges;
			reg = <0x2100000 0x100000>;

			adc@02198000 {
				clock-names = "adc";
				clocks = <0x1 0x7b>;
				compatible = "fsl,imx6ul-adc", "fsl,vf610-adc";
				interrupts = <0x0 0x64 0x4>;
				num-channels = <0x5>;
				pinctrl-0 = <0x27>;
				pinctrl-names = "default";
				reg = <0x2198000 0x4000>;
				status = "okay";
				vref-supply = <0x12>;
			};

			csi@021c4000 {
				clock-names = "disp-axi", "csi_mclk", "disp_dcic";
				clocks = <0x1 0x0 0x1 0x8a 0x1 0x0>;
				compatible = "fsl,imx6ul-csi", "fsl,imx6s-csi";
				interrupts = <0x0 0x7 0x4>;
				reg = <0x21c4000 0x4000>;
				status = "disabled";
			};

			csu@021c0000 {
				compatible = "fsl,imx6ul-csu";
				interrupts = <0x0 0x15 0x4>;
				reg = <0x21c0000 0x4000>;
				status = "disabled";
			};

			ethernet@02188000 {
				clock-names = "ipg", "ahb", "ptp", "enet_clk_ref", "enet_out";
				clocks = <0x1 0x90 0x1 0x91 0x1 0x30 0x1 0x2c 0x1 0x2c>;
				compatible = "fsl,imx6ul-fec", "fsl,imx6q-fec";
				fsl,magic-packet;
				fsl,num-rx-queues = <0x1>;
				fsl,num-tx-queues = <0x1>;
				fsl,wakeup_irq = <0x0>;
				interrupts = <0x0 0x76 0x4 0x0 0x77 0x4>;
				local-mac-address = [00 01 1f 2d 3e 4d];
				phy-handle = <0x24>;
				phy-mode = "rmii";
				phy-reset-duration = <0x1a>;
				phy-reset-gpios = <0x15 0x9 0x1>;
				pinctrl-0 = <0x23>;
				pinctrl-names = "default";
				reg = <0x2188000 0x4000>;
				status = "okay";
				stop-mode = <0xd 0x10 0x3>;
			};

			i2c@021a0000 {
				#address-cells = <0x1>;
				#size-cells = <0x0>;
				clock-frequency = <0x186a0>;
				clocks = <0x1 0x9c>;
				compatible = "fsl,imx6ul-i2c", "fsl,imx21-i2c";
				interrupts = <0x0 0x24 0x4>;
				pinctrl-0 = <0x28>;
				pinctrl-names = "default";
				reg = <0x21a0000 0x4000>;
				status = "okay";
			};

			i2c@021a4000 {
				#address-cells = <0x1>;
				#size-cells = <0x0>;
				clock_frequency = <0x186a0>;
				clocks = <0x1 0x9d>;
				compatible = "fsl,imx6ul-i2c", "fsl,imx21-i2c";
				interrupts = <0x0 0x25 0x4>;
				pinctrl-0 = <0x29>;
				pinctrl-names = "default";
				reg = <0x21a4000 0x4000>;
				status = "okay";

				gt9xx@5d {
					compatible = "goodix,gt9xx";
					goodix,auto-update = <0x0>;
					goodix,auto-update-cfg = <0x0>;
					goodix,cfg-group0 = [6b 00 04 58 02 05 0d 00 01 0f 28 0f 50 32 03 05 00 00 00 00 00 00 00 00 00 00 00 8a 2a 0c 45 47 0c 08 00 00 00 40 03 2c 00 01 00 00 00 03 64 32 00 00 00 28 64 94 d5 02 07 00 00 04 95 2c 00 8b 34 00 82 3f 00 7d 4c 00 7a 5b 00 7a 00 00 00 00 00 00 00 00 00 00 00 00 00 00 00 00 00 00 00 00 00 00 00 00 00 00 00 00 00 00 00 00 00 00 00 00 18 16 14 12 10 0e 0c 0a 08 06 04 02 ff ff 00 00 00 00 00 00 00 00 00 00 00 00 00 00 00 00 16 18 1c 1d 1e 1f 20 21 22 24 13 12 10 0f 0a 08 06 04 02 00 ff ff ff ff ff ff 00 00 00 00 00 00 00 00 00 00 00 00 00 00 00 00 79 01];
					goodix,cfg-group1 = [97 e0 01 10 01 05 0d 00 01 00 00 05 5a 46 53 11 00 00 11 11 14 14 14 22 0a 04 00 00 00 00 00 00 53 00 14 00 00 84 00 00 3c 00 00 64 1e 28 87 27 08 32 34 05 0d 20 33 60 11 02 24 00 00 64 80 80 14 02 00 00 54 89 68 85 6d 82 72 80 76 7d 7b 7b 00 00 00 00 00 00 00 f0 50 3c ff ff 07 00 00 00 02 14 14 03 04 00 21 64 0a 00 00 00 00 00 00 00 00 00 00 00 00 00 00 00 00 00 00 00 00 00 00 00 00 00 32 20 50 3c 3c 00 00 00 00 00 0d 06 0c 05 0b 04 0a 03 ff ff ff ff ff ff 00 01 02 03 04 05 06 07 08 09 0a 0b 0c 0d ff ff ff ff ff ff ff ff ff ff ff ff 00 00 00 00 00 00 00 00 00 00 00 00 00 00 3c 00 05 1e 00 02 2a 1e 19 14 02 00 03 0a 05 00 00 00 00 00 00 00 01 ff ff 86 22 03 00 00 33 00 0f 00 00 00 50 3c 50 00 00 00 00 2a 01];
					goodix,cfg-group2 = [00 20 03 e0 01 05 3c 00 01 08 28 0c 50 32 03 05 00 00 00 00 00 00 00 17 19 1e 14 8b 2b 0d 33 35 0c 08 00 00 00 9a 03 11 00 01 00 00 00 00 00 32 00 00 00 20 58 94 c5 02 00 00 00 04 b0 23 00 93 2b 00 7b 35 00 69 41 00 5b 4f 00 5b 00 00 00 00 00 00 00 00 00 00 00 00 00 00 00 00 00 00 00 00 00 00 00 00 00 00 00 00 00 00 00 00 00 00 00 00 02 04 06 08 0a 0c 0e 10 12 14 16 18 1a ff 00 00 00 00 00 00 00 00 00 00 00 00 00 00 00 00 00 02 04 06 08 0a 0c 0f 10 12 13 16 18 1c 1d 1e 1f 20 21 22 24 26 ff ff ff ff 00 00 00 ff ff ff ff ff ff ff ff ff ff ff ff ff 48 01];
					goodix,create-wr-node = <0x1>;
					goodix,driver-send-cfg = <0x0>;
					goodix,esd-protect = <0x0>;
					goodix,int-sync = <0x0>;
					goodix,pen-suppress-finger = <0x0>;
					goodix,power-off-sleep = <0x0>;
					goodix,resume-in-workqueue = <0x0>;
					goodix,swap-x2y = <0x0>;
					goodix,type-a-report = <0x0>;
					goodix,wakeup-with-reset = <0x0>;
					interrupt-parent = <0xb>;
					interrupts = <0x5 0x2>;
					irq-flags = <0x2>;
					irq-gpios = <0xb 0x5 0x2>;
					pinctrl-0 = <0x2c 0x2d>;
					pinctrl-names = "default";
					reg = <0x5d>;
					reset-gpios = <0x15 0x2 0x1>;
					status = "okay";
					touchscreen-max-id = <0x5>;
					touchscreen-max-p = <0x400>;
					touchscreen-max-w = <0x400>;
					touchscreen-size-x = <0x320>;
					touchscreen-size-y = <0x1e0>;
				};

				sii902x@39 {
					bits-per-pixel = <0x10>;
					compatible = "SiI,sii902x";
					interrupt-parent = <0xb>;
					interrupts = <0x12 0x2>;
					mode_str = "1280x720M@60";
					pinctrl-0 = <0x2a>;
					pinctrl-names = "default";
					reg = <0x39>;
					reset-names = "sii902x";
					resets = <0x2b>;
					status = "okay";
				};

				wm8960@1a {
					clock-names = "mclk";
					clocks = <0x1 0xb4>;
					compatible = "wlf,wm8960";
					linux,phandle = <0x3b>;
					phandle = <0x3b>;
					reg = <0x1a>;
					wlf,shared-lrclk;
				};
			};

			i2c@021a8000 {
				#address-cells = <0x1>;
				#size-cells = <0x0>;
				clocks = <0x1 0x9e>;
				compatible = "fsl,imx6ul-i2c", "fsl,imx21-i2c";
				interrupts = <0x0 0x26 0x4>;
				reg = <0x21a8000 0x4000>;
				status = "disabled";
			};

			i2c@021f8000 {
				#address-cells = <0x1>;
				#size-cells = <0x0>;
				clocks = <0x1 0x9f>;
				compatible = "fsl,imx6ul-i2c", "fsl,imx21-i2c";
				interrupts = <0x0 0x23 0x4>;
				reg = <0x21f8000 0x4000>;
				status = "disabled";
			};

			lcdif@021c8000 {
				clock-names = "pix", "axi", "disp_axi";
				clocks = <0x1 0xa2 0x1 0xa1 0x1 0x0>;
				compatible = "fsl,imx6ul-lcdif", "fsl,imx28-lcdif";
				display = <0x31>;
				interrupts = <0x0 0x5 0x4>;
				pinctrl-0 = <0x2e 0x2f 0x30>;
				pinctrl-names = "default";
				reg = <0x21c8000 0x4000>;
				reset-gpios = <0x32 0x4 0x1>;
				status = "okay";

				display {
					bits-per-pixel = <0x18>;
					bus-width = <0x18>;
					linux,phandle = <0x31>;
					phandle = <0x31>;

					display-timings {
						native-mode = <0x33>;

						timing0_1024x768 {
							clock-frequency = <0x2faf080>;
							de-active = <0x1>;
							hactive = <0x400>;
							hback-porch = <0x8c>;
							hfront-porch = <0xa0>;
							hsync-active = <0x0>;
							hsync-len = <0x14>;
							linux,phandle = <0x33>;
							phandle = <0x33>;
							pixelclk-active = <0x0>;
							vactive = <0x258>;
							vback-porch = <0x14>;
							vfront-porch = <0xc>;
							vsync-active = <0x0>;
							vsync-len = <0x3>;
						};
					};
				};
			};

			mmdc@021b0000 {
				compatible = "fsl,imx6ul-mmdc", "fsl,imx6q-mmdc";
				reg = <0x21b0000 0x4000>;
			};

			ocotp-ctrl@021bc000 {
				clocks = <0x1 0xa5>;
				compatible = "fsl,imx6ull-ocotp", "syscon";
				linux,phandle = <0x1c>;
				phandle = <0x1c>;
				reg = <0x21bc000 0x4000>;
			};

			pxp@021cc000 {
				clock-names = "pxp_ipg", "pxp_axi";
				clocks = <0x1 0x0 0x1 0xaf>;
				compatible = "fsl,imx6ull-pxp-dma", "fsl,imx7d-pxp-dma";
				interrupts = <0x0 0x8 0x4 0x0 0x12 0x4>;
				reg = <0x21cc000 0x4000>;
				status = "okay";
			};

			qspi@021e0000 {
				#address-cells = <0x1>;
				#size-cells = <0x0>;
				clock-names = "qspi_en", "qspi";
				clocks = <0x1 0xb0 0x1 0xb0>;
				compatible = "fsl,imx6ull-qspi", "fsl,imx6ul-qspi";
				interrupts = <0x0 0x6b 0x4>;
				reg = <0x21e0000 0x4000 0x60000000 0x10000000>;
				reg-names = "QuadSPI", "QuadSPI-memory";
				status = "disabled";
			};

			romcp@021ac000 {
				compatible = "fsl,imx6ul-romcp", "syscon";
				reg = <0x21ac000 0x4000>;
			};

			serial@021e8000 {
				clock-names = "ipg", "per";
				clocks = <0x1 0xbf 0x1 0xc0>;
				compatible = "fsl,imx6ul-uart", "fsl,imx6q-uart", "fsl,imx21-uart";
				dma-names = "rx", "tx";
				dmas = <0x7 0x1b 0x4 0x0 0x7 0x1c 0x4 0x0>;
				interrupts = <0x0 0x1b 0x4>;
				reg = <0x21e8000 0x4000>;
				status = "disabled";
			};

			serial@021ec000 {
				clock-names = "ipg", "per";
				clocks = <0x1 0xc1 0x1 0xc2>;
				compatible = "fsl,imx6ul-uart", "fsl,imx6q-uart", "fsl,imx21-uart";
				dma-names = "rx", "tx";
				dmas = <0x7 0x1d 0x4 0x0 0x7 0x1e 0x4 0x0>;
				interrupts = <0x0 0x1c 0x4>;
				linux,rs485-enabled-at-boot-time;
				pinctrl-0 = <0x34 0x35>;
				pinctrl-names = "default";
				reg = <0x21ec000 0x4000>;
				rs485-rts-active-high;
				rs485-rts-delay = <0x64 0x64>;
				rs485-rx-during-tx;
				status = "okay";
			};

			serial@021f0000 {
				clock-names = "ipg", "per";
				clocks = <0x1 0xc3 0x1 0xc4>;
				compatible = "fsl,imx6ul-uart", "fsl,imx6q-uart", "fsl,imx21-uart";
				dma-names = "rx", "tx";
				dmas = <0x7 0x1f 0x4 0x0 0x7 0x20 0x4 0x0>;
				interrupts = <0x0 0x1d 0x4>;
				reg = <0x21f0000 0x4000>;
				status = "disabled";
			};

			serial@021f4000 {
				clock-names = "ipg", "per";
				clocks = <0x1 0xc5 0x1 0xc6>;
				compatible = "fsl,imx6ul-uart", "fsl,imx6q-uart", "fsl,imx21-uart";
				dma-names = "rx", "tx";
				dmas = <0x7 0x21 0x4 0x0 0x7 0x22 0x4 0x0>;
				interrupts = <0x0 0x1e 0x4>;
				reg = <0x21f4000 0x4000>;
				status = "disabled";
			};

			serial@021fc000 {
				clock-names = "ipg", "per";
				clocks = <0x1 0xc7 0x1 0xc8>;
				compatible = "fsl,imx6ul-uart", "fsl,imx6q-uart", "fsl,imx21-uart";
				dma-names = "rx", "tx";
				dmas = <0x7 0x0 0x4 0x0 0x7 0x2f 0x4 0x0>;
				interrupts = <0x0 0x11 0x4>;
				pinctrl-0 = <0x36>;
				pinctrl-names = "default";
				reg = <0x21fc000 0x4000>;
				status = "okay";
			};

			usb@02184000 {
				adp-disable;
				ahb-burst-config = <0x0>;
				clocks = <0x1 0xcd>;
				compatible = "fsl,imx6ul-usb", "fsl,imx27-usb";
				dr_mode = "otg";
				fsl,anatop = <0x1b>;
				fsl,usbmisc = <0x21 0x0>;
				fsl,usbphy = <0x20>;
				hnp-disable;
				interrupts = <0x0 0x2b 0x4>;
				reg = <0x2184000 0x200>;
				rx-burst-size-dword = <0x10>;
				srp-disable;
				status = "okay";
				tx-burst-size-dword = <0x10>;
			};

			usb@02184200 {
				ahb-burst-config = <0x0>;
				clocks = <0x1 0xcd>;
				compatible = "fsl,imx6ul-usb", "fsl,imx27-usb";
				disable-over-current;
				dr_mode = "host";
				fsl,usbmisc = <0x21 0x1>;
				fsl,usbphy = <0x22>;
				interrupts = <0x0 0x2a 0x4>;
				reg = <0x2184200 0x200>;
				rx-burst-size-dword = <0x10>;
				status = "okay";
				tx-burst-size-dword = <0x10>;
			};

			usbmisc@02184800 {
				#index-cells = <0x1>;
				compatible = "fsl,imx6ul-usbmisc", "fsl,imx6q-usbmisc";
				linux,phandle = <0x21>;
				phandle = <0x21>;
				reg = <0x2184800 0x200>;
			};

			usdhc@02190000 {
				assigned-clock-parents = <0x1 0x26>;
				assigned-clock-rates = <0x0 0x7de2900>;
				assigned-clocks = <0x1 0x40 0x1 0xce>;
				bus-width = <0x4>;
				cd-gpios = <0xb 0x13 0x1>;
				clock-names = "ipg", "ahb", "per";
				clocks = <0x1 0xce 0x1 0xce 0x1 0xce>;
				compatible = "fsl,imx6ull-usdhc", "fsl,imx6sx-usdhc";
				enable-sdio-wakeup;
				fsl,tuning-step = <0x2>;
				interrupts = <0x0 0x16 0x4>;
				keep-power-in-suspend;
				pinctrl-0 = <0x25>;
				pinctrl-names = "default";
				reg = <0x2190000 0x4000>;
				status = "okay";
			};

			usdhc@02194000 {
				assigned-clock-parents = <0x1 0x26>;
				assigned-clock-rates = <0x0 0x7de2900>;
				assigned-clocks = <0x1 0x41 0x1 0xcf>;
				bus-width = <0x8>;
				clock-names = "ipg", "ahb", "per";
				clocks = <0x1 0xcf 0x1 0xcf 0x1 0xcf>;
				compatible = "fsl,imx6ull-usdhc", "fsl,imx6sx-usdhc";
				fsl,tuning-step = <0x2>;
				interrupts = <0x0 0x17 0x4>;
				non-removable;
				pinctrl-0 = <0x26>;
				pinctrl-names = "default";
				reg = <0x2194000 0x4000>;
				status = "okay";
			};

			weim@021b8000 {
				clocks = <0x1 0x0>;
				compatible = "fsl,imx6ul-weim", "fsl,imx6q-weim";
				interrupts = <0x0 0xe 0x4>;
				reg = <0x21b8000 0x4000>;
			};
		};

		aips-bus@02200000 {
			#address-cells = <0x1>;
			#size-cells = <0x1>;
			compatible = "fsl,aips-bus", "simple-bus";
			ranges;
			reg = <0x2200000 0x100000>;

			dcp@02280000 {
				clock-names = "dcp";
				clocks = <0x1 0xe7>;
				compatible = "fsl,imx6sl-dcp";
				interrupts = <0x0 0x2e 0x4 0x0 0x2f 0x4 0x0 0x30 0x4>;
				reg = <0x2280000 0x4000>;
			};

			epdc@0228c000 {
				clock-names = "epdc_axi", "epdc_pix";
				clocks = <0x1 0xeb 0x1 0xec>;
				compatible = "fsl,imx7d-epdc";
				interrupts = <0x0 0x70 0x4>;
				reg = <0x228c000 0x4000>;
				status = "disabled";
			};

			iomuxc-snvs@02290000 {
				compatible = "fsl,imx6ull-iomuxc-snvs";
				pinctrl-0 = <0x37>;
				pinctrl-names = "default_snvs";
				reg = <0x2290000 0x10000>;

				imx6ul-evk {

					hoggrp-2 {
						fsl,pins = <0x2c 0x70 0x0 0x5 0x0 0x1b0b0 0x20 0x64 0x0 0x5 0x0 0x1b0b0 0xc 0x50 0x0 0x5 0x0 0x110a0>;
						linux,phandle = <0x37>;
						phandle = <0x37>;
					};

					ledgrp {
						fsl,pins = <0x14 0x58 0x0 0x5 0x0 0x110a0>;
						linux,phandle = <0x39>;
						phandle = <0x39>;
					};

					spi4grp {
						fsl,pins = <0x0 0x44 0x0 0x5 0x0 0x70a1 0x4 0x48 0x0 0x5 0x0 0x70a1 0x24 0x68 0x0 0x5 0x0 0x70a1 0x28 0x6c 0x0 0x5 0x0 0x80000000>;
						linux,phandle = <0x3d>;
						phandle = <0x3d>;
					};

					tscresetgrp {
						fsl,pins = <0x10 0x54 0x0 0x5 0x0 0x110a0>;
						linux,phandle = <0x2c>;
						phandle = <0x2c>;
					};

					uart3_rs485 {
						fsl,pins = <0x8 0x4c 0x0 0x5 0x0 0x1b0b0>;
						linux,phandle = <0x35>;
						phandle = <0x35>;
					};
				};
			};

			rngb@02284000 {
				clocks = <0x1 0x0>;
				compatible = "fsl,imx6sl-rng", "fsl,imx-rng", "imx-rng";
				interrupts = <0x0 0x6 0x4>;
				reg = <0x2284000 0x4000>;
			};

			serial@02288000 {
				clock-names = "ipg", "per";
				clocks = <0x1 0xcb 0x1 0xcc>;
				compatible = "fsl,imx6ul-uart", "fsl,imx6q-uart", "fsl,imx21-uart";
				dma-names = "rx", "tx";
				dmas = <0x7 0x2d 0x4 0x0 0x7 0x2e 0x4 0x0>;
				interrupts = <0x0 0x28 0x4>;
				reg = <0x2288000 0x4000>;
				status = "disabled";
			};

			snvs-gpr@0x02294000 {
				compatible = "fsl, imx6ull-snvs-gpr";
				reg = <0x2294000 0x10000>;
			};
		};

		busfreq {
			clock-names = "pll2_pfd2_396m", "pll2_198m", "pll2_bus", "arm", "pll3_usb_otg", "periph", "periph_pre", "periph_clk2", "periph_clk2_sel", "osc", "ahb", "ocram", "periph2", "periph2_pre", "periph2_clk2", "periph2_clk2_sel", "step", "mmdc", "pll1_bypass_src", "pll1_bypass", "pll1_sys", "pll1_sw", "pll1";
			clocks = <0x1 0x26 0x1 0x35 0x1 0x1a 0x1 0x5d 0x1 0x1b 0x1 0x55 0x1 0x3c 0x1 0x5e 0x1 0x3e 0x1 0x3 0x1 0x60 0x1 0xd4 0x1 0x56 0x1 0x3d 0x1 0x5f 0x1 0x3f 0x1 0x38 0x1 0xa3 0x1 0x4 0x1 0x12 0x1 0x19 0x1 0x39 0x1 0xb>;
			compatible = "fsl,imx_busfreq";
			fsl,max_ddr_freq = <0x17d78400>;
		};

		dma-apbh@01804000 {
			#dma-cells = <0x1>;
			clocks = <0x1 0x80>;
			compatible = "fsl,imx6ul-dma-apbh", "fsl,imx28-dma-apbh";
			dma-channels = <0x4>;
			interrupt-names = "gpmi0", "gpmi1", "gpmi2", "gpmi3";
			interrupts = <0x0 0xd 0x4 0x0 0xd 0x4 0x0 0xd 0x4 0x0 0xd 0x4>;
			linux,phandle = <0x6>;
			phandle = <0x6>;
			reg = <0x1804000 0x2000>;
		};

		gpmi-nand@01806000 {
			#address-cells = <0x1>;
			#size-cells = <0x1>;
			clock-names = "gpmi_io", "gpmi_apb", "gpmi_bch", "gpmi_bch_apb", "per1_bch";
			clocks = <0x1 0x85 0x1 0x86 0x1 0x84 0x1 0x83 0x1 0xdc>;
			compatible = "fsl,imx6ull-gpmi-nand", "fsl, imx6ul-gpmi-nand";
			dma-names = "rx-tx";
			dmas = <0x6 0x0>;
			interrupt-names = "bch";
			interrupts = <0x0 0xf 0x4>;
			reg = <0x1806000 0x2000 0x1808000 0x4000>;
			reg-names = "gpmi-nand", "bch";
			status = "disabled";
		};

		pmu {
			compatible = "arm,cortex-a7-pmu";
			interrupts = <0x0 0x5e 0x4>;
			status = "disabled";
		};

		sram@00900000 {
			compatible = "fsl,lpm-sram";
			reg = <0x900000 0x4000>;
		};

		sram@00904000 {
			compatible = "fsl,ddr-lpm-sram";
			reg = <0x904000 0x1000>;
		};

		sram@00905000 {
			compatible = "mmio-sram";
			linux,phandle = <0x5>;
			phandle = <0x5>;
			reg = <0x905000 0x1b000>;
		};

		sram@00918000 {
			compatible = "fsl,optee-lpm-sram";
			overw_reg = <0x5 0x905000 0x13000>;
			reg = <0x918000 0x8000>;
		};
	};

	sound {
		asrc-controller = <0x3c>;
		audio-codec = <0x3b>;
		audio-routing = "Headphone Jack", "HP_L", "Headphone Jack", "HP_R", "Ext Spk", "SPK_LP", "Ext Spk", "SPK_LN", "Ext Spk", "SPK_RP", "Ext Spk", "SPK_RN", "LINPUT2", "Mic Jack", "LINPUT3", "Mic Jack", "RINPUT1", "Main MIC", "RINPUT2", "Main MIC", "Mic Jack", "MICB", "Main MIC", "MICB", "CPU-Playback", "ASRC-Playback", "Playback", "CPU-Playback", "ASRC-Capture", "CPU-Capture", "CPU-Capture", "Capture";
		codec-master;
		compatible = "fsl,imx6ul-evk-wm8960", "fsl,imx-audio-wm8960";
		cpu-dai = <0x3a>;
		gpr = <0xd 0x4 0x100000 0x100000>;
		hp-det = <0x3 0x0>;
		model = "wm8960-audio";
		status = "okay";
	};

	spi4 {
		#address-cells = <0x1>;
		#size-cells = <0x0>;
		compatible = "spi-gpio";
		cs-gpios = <0x15 0x7 0x0>;
		gpio-mosi = <0x15 0xa 0x0>;
		gpio-sck = <0x15 0xb 0x0>;
		num-chipselects = <0x1>;
		pinctrl-0 = <0x3d>;
		pinctrl-assert-gpios = <0x15 0x8 0x1>;
		pinctrl-names = "default";
		status = "okay";

		gpio_spi@0 {
			#gpio-cells = <0x2>;
			compatible = "fairchild,74hc595";
			gpio-controller;
			linux,phandle = <0x3e>;
			phandle = <0x3e>;
			reg = <0x0>;
			registers-default = [57];
			registers-number = <0x1>;
			spi-max-frequency = <0x2710>;
		};
	};
};
